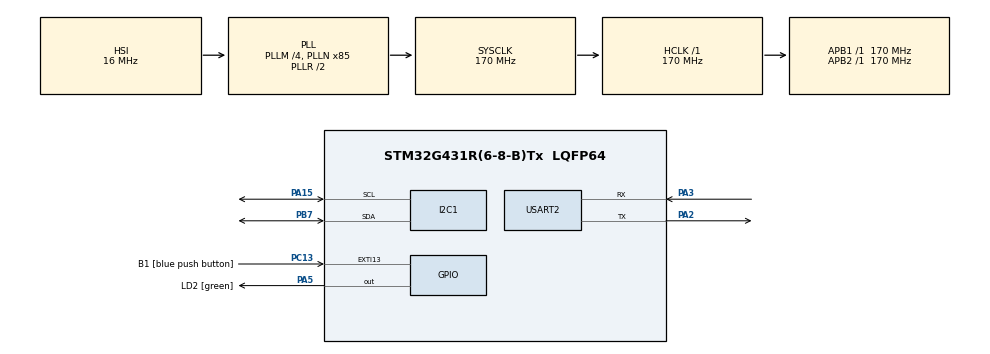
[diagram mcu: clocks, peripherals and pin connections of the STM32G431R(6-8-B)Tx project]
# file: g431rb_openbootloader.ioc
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I2C1.Timing=0x30A0A7FB
Mcu.Family=STM32G4
Mcu.Name=STM32G431R(6-8-B)Tx
Mcu.Package=LQFP64
NVIC.PriorityGroup=NVIC_PRIORITYGROUP_4
PA13.GPIO_Label=T_SWDIO
PA13.Mode=Serial_Wire
PA13.Signal=SYS_JTMS-SWDIO
PA14.GPIO_Label=T_SWCLK
PA14.Mode=Serial_Wire
PA14.Signal=SYS_JTCK-SWCLK
PA15.Mode=I2C
PA15.Signal=I2C1_SCL
PA2.Mode=Asynchronous
PA2.Signal=USART2_TX
PA3.Mode=Asynchronous
PA3.Signal=USART2_RX
PA5.GPIO_Label=LD2 [green]
PA5.Signal=GPIO_Output
PB3.GPIO_Label=T_SWO
PB3.Signal=SYS_JTDO-SWO
PB7.Mode=I2C
PB7.Signal=I2C1_SDA
PC13.GPIO_Label=B1 [blue push button]
PC13.Signal=GPXTI13
PC14-OSC32_IN.Mode=LSE-External-Oscillator
PC14-OSC32_IN.Signal=RCC_OSC32_IN
PC15-OSC32_OUT.Mode=LSE-External-Oscillator
PC15-OSC32_OUT.Signal=RCC_OSC32_OUT
PF0-OSC_IN.Mode=HSE-External-Oscillator
PF0-OSC_IN.Signal=RCC_OSC_IN
PF1-OSC_OUT.Mode=HSE-External-Oscillator
PF1-OSC_OUT.Signal=RCC_OSC_OUT
ProjectManager.HeapSize=0x200
ProjectManager.StackSize=0x400
ProjectManager.TargetToolchain=STM32CubeIDE
RCC.ADC12Freq_Value=170000000
RCC.AHBFreq_Value=170000000
RCC.APB1Freq_Value=170000000
RCC.APB1TimFreq_Value=170000000
RCC.APB2Freq_Value=170000000
RCC.APB2TimFreq_Value=170000000
RCC.CortexFreq_Value=170000000
RCC.EXTERNAL_CLOCK_VALUE=12288000
RCC.HCLKFreq_Value=170000000
RCC.HSE_VALUE=24000000
RCC.HSI48_VALUE=48000000
RCC.HSI_VALUE=16000000
RCC.PLLM=RCC_PLLM_DIV4
RCC.PLLN=85
RCC.RTCClockSelection=RCC_RTCCLKSOURCE_LSE
RCC.SYSCLKFreq_VALUE=170000000
RCC.SYSCLKSource=RCC_SYSCLKSOURCE_PLLCLK
RCC.USBFreq_Value=170000000
RCC.VCOOutputFreq_Value=340000000
USART2.VirtualMode-Asynchronous=VM_ASYNC
VP_IWDG_VS_IWDG.Mode=IWDG_Activate
VP_SYS_VS_DBSignals.Mode=DisableDeadBatterySignals
board=NUCLEO-G431RB

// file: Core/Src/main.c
/* USER CODE BEGIN Header */
/**
  ******************************************************************************
  * @file           : main.c
  * @brief          : Main program body
  ******************************************************************************
  * @attention
  *
  * Copyright (c) 2024 STMicroelectronics.
  * All rights reserved.
  *
  * This software is licensed under terms that can be found in the LICENSE file
  * in the root directory of this software component.
  * If no LICENSE file comes with this software, it is provided AS-IS.
  *
  ******************************************************************************
  */
/* USER CODE END Header */
#include "main.h"

IWDG_HandleTypeDef hiwdg;

void SystemClock_Config(void);
static void MX_GPIO_Init(void);
static void MX_USART2_UART_Init(void);
static void MX_I2C1_Init(void);
static void MX_IWDG_Init(void);

int main(void)
{

  /* MCU Configuration--------------------------------------------------------*/

  /* Reset of all peripherals, Initializes the Flash interface and the Systick. */
  HAL_Init();

  /* Configure the system clock */
  SystemClock_Config();

  /* Initialize all configured peripherals */
  MX_GPIO_Init();
  MX_USART2_UART_Init();
  MX_I2C1_Init();
  MX_IWDG_Init();
  /* USER CODE BEGIN 2 */
  OpenBootloader_Init();
  /* USER CODE END 2 */

  /* Infinite loop */
  /* USER CODE BEGIN WHILE */
  while (1)
  {
	  OpenBootloader_ProtocolDetection();
	  //HAL_Delay(10);
    /* USER CODE END WHILE */

  }
}

void SystemClock_Config(void)
{
  RCC_OscInitTypeDef RCC_OscInitStruct = {0};
  RCC_ClkInitTypeDef RCC_ClkInitStruct = {0};

  /** Configure the main internal regulator output voltage
  */
  HAL_PWREx_ControlVoltageScaling(PWR_REGULATOR_VOLTAGE_SCALE1_BOOST);

  /** Initializes the RCC Oscillators according to the specified parameters
  * in the RCC_OscInitTypeDef structure.
  */
  RCC_OscInitStruct.OscillatorType = RCC_OSCILLATORTYPE_HSI|RCC_OSCILLATORTYPE_LSI;
  RCC_OscInitStruct.HSIState = RCC_HSI_ON;
  RCC_OscInitStruct.HSICalibrationValue = RCC_HSICALIBRATION_DEFAULT;
  RCC_OscInitStruct.LSIState = RCC_LSI_ON;
  RCC_OscInitStruct.PLL.PLLState = RCC_PLL_ON;
  RCC_OscInitStruct.PLL.PLLSource = RCC_PLLSOURCE_HSI;
  RCC_OscInitStruct.PLL.PLLM = RCC_PLLM_DIV4;
  RCC_OscInitStruct.PLL.PLLN = 85;
  RCC_OscInitStruct.PLL.PLLP = RCC_PLLP_DIV2;
  RCC_OscInitStruct.PLL.PLLQ = RCC_PLLQ_DIV2;
  RCC_OscInitStruct.PLL.PLLR = RCC_PLLR_DIV2;
  if (HAL_RCC_OscConfig(&RCC_OscInitStruct) != HAL_OK)
  {
    Error_Handler();
  }

  /** Initializes the CPU, AHB and APB buses clocks
  */
  RCC_ClkInitStruct.ClockType = RCC_CLOCKTYPE_HCLK|RCC_CLOCKTYPE_SYSCLK
                              |RCC_CLOCKTYPE_PCLK1|RCC_CLOCKTYPE_PCLK2;
  RCC_ClkInitStruct.SYSCLKSource = RCC_SYSCLKSOURCE_PLLCLK;
  RCC_ClkInitStruct.AHBCLKDivider = RCC_SYSCLK_DIV1;
  RCC_ClkInitStruct.APB1CLKDivider = RCC_HCLK_DIV1;
  RCC_ClkInitStruct.APB2CLKDivider = RCC_HCLK_DIV1;

  if (HAL_RCC_ClockConfig(&RCC_ClkInitStruct, FLASH_LATENCY_4) != HAL_OK)
  {
    Error_Handler();
  }
}

static void MX_I2C1_Init(void)
{

  LL_I2C_InitTypeDef I2C_InitStruct = {0};

  LL_GPIO_InitTypeDef GPIO_InitStruct = {0};
  RCC_PeriphCLKInitTypeDef PeriphClkInit = {0};

  /** Initializes the peripherals clocks
  */
  PeriphClkInit.PeriphClockSelection = RCC_PERIPHCLK_I2C1;
  PeriphClkInit.I2c1ClockSelection = RCC_I2C1CLKSOURCE_PCLK1;
  if (HAL_RCCEx_PeriphCLKConfig(&PeriphClkInit) != HAL_OK)
  {
    Error_Handler();
  }

  LL_AHB2_GRP1_EnableClock(LL_AHB2_GRP1_PERIPH_GPIOA);
  LL_AHB2_GRP1_EnableClock(LL_AHB2_GRP1_PERIPH_GPIOB);
  /**I2C1 GPIO Configuration
  PA15   ------> I2C1_SCL
  PB7   ------> I2C1_SDA
  */
  GPIO_InitStruct.Pin = LL_GPIO_PIN_15;
  GPIO_InitStruct.Mode = LL_GPIO_MODE_ALTERNATE;
  GPIO_InitStruct.Speed = LL_GPIO_SPEED_FREQ_LOW;
  GPIO_InitStruct.OutputType = LL_GPIO_OUTPUT_OPENDRAIN;
  GPIO_InitStruct.Pull = LL_GPIO_PULL_NO;
  GPIO_InitStruct.Alternate = LL_GPIO_AF_4;
  LL_GPIO_Init(GPIOA, &GPIO_InitStruct);

  GPIO_InitStruct.Pin = LL_GPIO_PIN_7;
  GPIO_InitStruct.Mode = LL_GPIO_MODE_ALTERNATE;
  GPIO_InitStruct.Speed = LL_GPIO_SPEED_FREQ_LOW;
  GPIO_InitStruct.OutputType = LL_GPIO_OUTPUT_OPENDRAIN;
  GPIO_InitStruct.Pull = LL_GPIO_PULL_NO;
  GPIO_InitStruct.Alternate = LL_GPIO_AF_4;
  LL_GPIO_Init(GPIOB, &GPIO_InitStruct);

  /* Peripheral clock enable */
  LL_APB1_GRP1_EnableClock(LL_APB1_GRP1_PERIPH_I2C1);

  /** I2C Initialization
  */
  I2C_InitStruct.PeripheralMode = LL_I2C_MODE_I2C;
  I2C_InitStruct.Timing = 0x30A0A7FB;
  I2C_InitStruct.AnalogFilter = LL_I2C_ANALOGFILTER_ENABLE;
  I2C_InitStruct.DigitalFilter = 0;
  I2C_InitStruct.OwnAddress1 = 0;
  I2C_InitStruct.TypeAcknowledge = LL_I2C_ACK;
  I2C_InitStruct.OwnAddrSize = LL_I2C_OWNADDRESS1_7BIT;
  LL_I2C_Init(I2C1, &I2C_InitStruct);
  LL_I2C_EnableAutoEndMode(I2C1);
  LL_I2C_SetOwnAddress2(I2C1, 0, LL_I2C_OWNADDRESS2_NOMASK);
  LL_I2C_DisableOwnAddress2(I2C1);
  LL_I2C_DisableGeneralCall(I2C1);
  LL_I2C_EnableClockStretching(I2C1);

}

static void MX_IWDG_Init(void)
{

  hiwdg.Instance = IWDG;
  hiwdg.Init.Prescaler = IWDG_PRESCALER_4;
  hiwdg.Init.Window = 4095;
  hiwdg.Init.Reload = 4095;
  if (HAL_IWDG_Init(&hiwdg) != HAL_OK)
  {
    Error_Handler();
  }

}

static void MX_USART2_UART_Init(void)
{

  LL_USART_InitTypeDef USART_InitStruct = {0};

  LL_GPIO_InitTypeDef GPIO_InitStruct = {0};
  RCC_PeriphCLKInitTypeDef PeriphClkInit = {0};

  /** Initializes the peripherals clocks
  */
  PeriphClkInit.PeriphClockSelection = RCC_PERIPHCLK_USART2;
  PeriphClkInit.Usart2ClockSelection = RCC_USART2CLKSOURCE_PCLK1;
  if (HAL_RCCEx_PeriphCLKConfig(&PeriphClkInit) != HAL_OK)
  {
    Error_Handler();
  }

  /* Peripheral clock enable */
  LL_APB1_GRP1_EnableClock(LL_APB1_GRP1_PERIPH_USART2);

  LL_AHB2_GRP1_EnableClock(LL_AHB2_GRP1_PERIPH_GPIOA);
  /**USART2 GPIO Configuration
  PA2   ------> USART2_TX
  PA3   ------> USART2_RX
  */
  GPIO_InitStruct.Pin = LL_GPIO_PIN_2;
  GPIO_InitStruct.Mode = LL_GPIO_MODE_ALTERNATE;
  GPIO_InitStruct.Speed = LL_GPIO_SPEED_FREQ_LOW;
  GPIO_InitStruct.OutputType = LL_GPIO_OUTPUT_PUSHPULL;
  GPIO_InitStruct.Pull = LL_GPIO_PULL_NO;
  GPIO_InitStruct.Alternate = LL_GPIO_AF_7;
  LL_GPIO_Init(GPIOA, &GPIO_InitStruct);

  GPIO_InitStruct.Pin = LL_GPIO_PIN_3;
  GPIO_InitStruct.Mode = LL_GPIO_MODE_ALTERNATE;
  GPIO_InitStruct.Speed = LL_GPIO_SPEED_FREQ_LOW;
  GPIO_InitStruct.OutputType = LL_GPIO_OUTPUT_PUSHPULL;
  GPIO_InitStruct.Pull = LL_GPIO_PULL_NO;
  GPIO_InitStruct.Alternate = LL_GPIO_AF_7;
  LL_GPIO_Init(GPIOA, &GPIO_InitStruct);

  USART_InitStruct.PrescalerValue = LL_USART_PRESCALER_DIV1;
  USART_InitStruct.BaudRate = 115200;
  USART_InitStruct.DataWidth = LL_USART_DATAWIDTH_8B;
  USART_InitStruct.StopBits = LL_USART_STOPBITS_1;
  USART_InitStruct.Parity = LL_USART_PARITY_NONE;
  USART_InitStruct.TransferDirection = LL_USART_DIRECTION_TX_RX;
  USART_InitStruct.HardwareFlowControl = LL_USART_HWCONTROL_NONE;
  USART_InitStruct.OverSampling = LL_USART_OVERSAMPLING_16;
  LL_USART_Init(USART2, &USART_InitStruct);
  LL_USART_SetTXFIFOThreshold(USART2, LL_USART_FIFOTHRESHOLD_1_8);
  LL_USART_SetRXFIFOThreshold(USART2, LL_USART_FIFOTHRESHOLD_1_8);
  LL_USART_DisableFIFO(USART2);
  LL_USART_ConfigAsyncMode(USART2);

  LL_USART_Enable(USART2);

  /* Polling USART2 initialisation */
  while((!(LL_USART_IsActiveFlag_TEACK(USART2))) || (!(LL_USART_IsActiveFlag_REACK(USART2))))
  {
  }

}

static void MX_GPIO_Init(void)
{
  GPIO_InitTypeDef GPIO_InitStruct = {0};

  /* GPIO Ports Clock Enable */
  __HAL_RCC_GPIOC_CLK_ENABLE();
  __HAL_RCC_GPIOF_CLK_ENABLE();
  __HAL_RCC_GPIOA_CLK_ENABLE();
  __HAL_RCC_GPIOB_CLK_ENABLE();

  /*Configure GPIO pin Output Level */
  HAL_GPIO_WritePin(LD2_GPIO_Port, LD2_Pin, GPIO_PIN_RESET);

  /*Configure GPIO pin : B1_Pin */
  GPIO_InitStruct.Pin = B1_Pin;
  GPIO_InitStruct.Mode = GPIO_MODE_IT_RISING;
  GPIO_InitStruct.Pull = GPIO_NOPULL;
  HAL_GPIO_Init(B1_GPIO_Port, &GPIO_InitStruct);

  /*Configure GPIO pin : LD2_Pin */
  GPIO_InitStruct.Pin = LD2_Pin;
  GPIO_InitStruct.Mode = GPIO_MODE_OUTPUT_PP;
  GPIO_InitStruct.Pull = GPIO_NOPULL;
  GPIO_InitStruct.Speed = GPIO_SPEED_FREQ_LOW;
  HAL_GPIO_Init(LD2_GPIO_Port, &GPIO_InitStruct);

}

void Error_Handler(void)
{
  __disable_irq();
  while (1)
  {
  }
}
